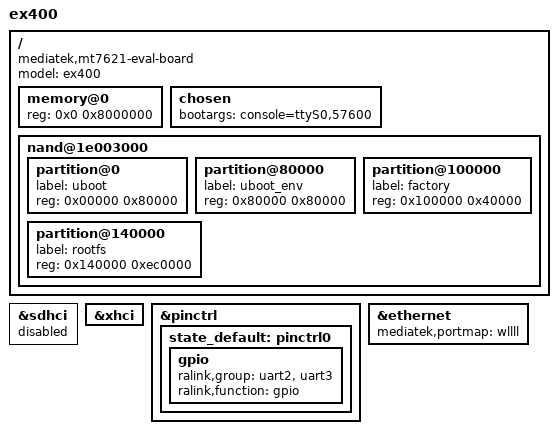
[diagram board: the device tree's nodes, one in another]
/dts-v1/;

#include "ex400.dtsi"

/ {
	compatible = "mediatek,mt7621-eval-board", "mediatek,mt7621-soc";
	model = "ex400";

	memory@0 {
		device_type = "memory";
		reg = <0x0 0x8000000>;
	};

	chosen {
		bootargs = "console=ttyS0,57600";
	};

	nand@1e003000 {
		partition@0 {
			label = "uboot";
			reg = <0x00000 0x80000>; /* 64 KB */
		};

		partition@80000 {
			label = "uboot_env";
			reg = <0x80000 0x80000>; /* 64 KB */
		};

		partition@100000 {
			label = "factory";
			reg = <0x100000 0x40000>;
		};

		partition@140000 {
			label = "rootfs";
			reg = <0x140000 0xec0000>;
		};
	};
};

&sdhci {
	status = "disabled";
};

&xhci {
	status = "okay";
};

&pinctrl {
	state_default: pinctrl0 {
		gpio {
			ralink,group =  "uart2", "uart3";
			ralink,function = "gpio";
		};
	};
};

&ethernet {
        mediatek,portmap = "wllll";	
};
